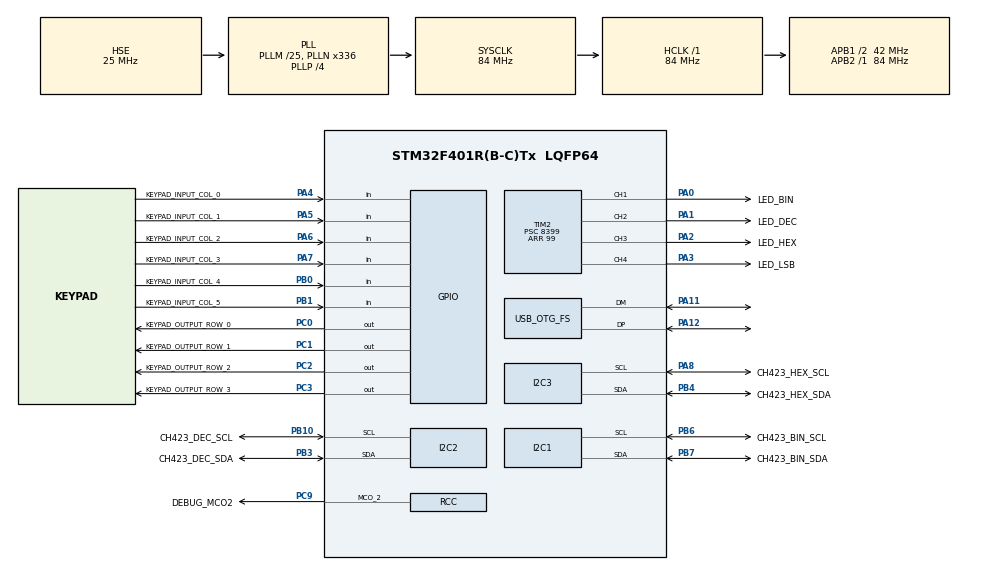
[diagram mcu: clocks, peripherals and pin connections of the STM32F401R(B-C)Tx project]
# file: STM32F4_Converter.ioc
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Dma.I2C1_TX.0.Direction=DMA_MEMORY_TO_PERIPH
Dma.I2C1_TX.0.FIFOMode=DMA_FIFOMODE_DISABLE
Dma.I2C1_TX.0.Instance=DMA1_Stream6
Dma.I2C1_TX.0.MemDataAlignment=DMA_MDATAALIGN_BYTE
Dma.I2C1_TX.0.MemInc=DMA_MINC_ENABLE
Dma.I2C1_TX.0.Mode=DMA_NORMAL
Dma.I2C1_TX.0.PeriphDataAlignment=DMA_PDATAALIGN_BYTE
Dma.I2C1_TX.0.PeriphInc=DMA_PINC_DISABLE
Dma.I2C1_TX.0.Priority=DMA_PRIORITY_LOW
Dma.I2C2_TX.1.Direction=DMA_MEMORY_TO_PERIPH
Dma.I2C2_TX.1.FIFOMode=DMA_FIFOMODE_DISABLE
Dma.I2C2_TX.1.Instance=DMA1_Stream7
Dma.I2C2_TX.1.MemDataAlignment=DMA_MDATAALIGN_BYTE
Dma.I2C2_TX.1.MemInc=DMA_MINC_ENABLE
Dma.I2C2_TX.1.Mode=DMA_NORMAL
Dma.I2C2_TX.1.PeriphDataAlignment=DMA_PDATAALIGN_BYTE
Dma.I2C2_TX.1.PeriphInc=DMA_PINC_DISABLE
Dma.I2C2_TX.1.Priority=DMA_PRIORITY_LOW
Dma.I2C3_TX.2.Direction=DMA_MEMORY_TO_PERIPH
Dma.I2C3_TX.2.FIFOMode=DMA_FIFOMODE_DISABLE
Dma.I2C3_TX.2.Instance=DMA1_Stream4
Dma.I2C3_TX.2.MemDataAlignment=DMA_MDATAALIGN_BYTE
Dma.I2C3_TX.2.MemInc=DMA_MINC_ENABLE
Dma.I2C3_TX.2.Mode=DMA_NORMAL
Dma.I2C3_TX.2.PeriphDataAlignment=DMA_PDATAALIGN_BYTE
Dma.I2C3_TX.2.PeriphInc=DMA_PINC_DISABLE
Dma.I2C3_TX.2.Priority=DMA_PRIORITY_LOW
Dma.Request0=I2C1_TX
Dma.Request1=I2C2_TX
Dma.Request2=I2C3_TX
FREERTOS.Tasks01=defaultTask,-2,512,StartDefaultTask,Default,NULL,Dynamic,NULL,NULL
I2C1.I2C_Mode=I2C_Fast
I2C2.I2C_Mode=I2C_Fast
I2C3.I2C_Mode=I2C_Fast
Mcu.Family=STM32F4
Mcu.Name=STM32F401R(B-C)Tx
Mcu.Package=LQFP64
NVIC.DMA1_Stream4_IRQn=true\:10\:0\:true\:false\:true\:true\:false\:true
NVIC.DMA1_Stream6_IRQn=true\:10\:0\:true\:false\:true\:true\:false\:true
NVIC.DMA1_Stream7_IRQn=true\:10\:0\:true\:false\:true\:true\:false\:true
NVIC.OTG_FS_IRQn=true\:15\:0\:true\:false\:true\:false\:false\:true
NVIC.PriorityGroup=NVIC_PRIORITYGROUP_4
NVIC.TIM1_UP_TIM10_IRQn=true\:0\:0\:false\:false\:true\:false\:false\:true
NVIC.TIM3_IRQn=true\:5\:0\:true\:false\:true\:true\:true\:true
NVIC.TimeBase=TIM1_UP_TIM10_IRQn
NVIC.TimeBaseIP=TIM1
PA0-WKUP.GPIO_Label=LED_BIN
PA0-WKUP.Signal=S_TIM2_CH1_ETR
PA1.GPIO_Label=LED_DEC
PA1.Signal=S_TIM2_CH2
PA11.Mode=Device_Only
PA11.Signal=USB_OTG_FS_DM
PA12.Mode=Device_Only
PA12.Signal=USB_OTG_FS_DP
PA13.GPIO_Label=SWD_SWDIO
PA13.Mode=Serial_Wire
PA13.Signal=SYS_JTMS-SWDIO
PA14.GPIO_Label=SWD_SWCLK
PA14.Mode=Serial_Wire
PA14.Signal=SYS_JTCK-SWCLK
PA2.GPIO_Label=LED_HEX
PA2.Signal=S_TIM2_CH3
PA3.GPIO_Label=LED_LSB
PA3.Signal=S_TIM2_CH4
PA4.GPIO_Label=KEYPAD_INPUT_COL_0
PA4.Signal=GPIO_Input
PA5.GPIO_Label=KEYPAD_INPUT_COL_1
PA5.Signal=GPIO_Input
PA6.GPIO_Label=KEYPAD_INPUT_COL_2
PA6.Signal=GPIO_Input
PA7.GPIO_Label=KEYPAD_INPUT_COL_3
PA7.Signal=GPIO_Input
PA8.GPIO_Label=CH423_HEX_SCL
PA8.Mode=I2C
PA8.Signal=I2C3_SCL
PB0.GPIO_Label=KEYPAD_INPUT_COL_4
PB0.Signal=GPIO_Input
PB1.GPIO_Label=KEYPAD_INPUT_COL_5
PB1.Signal=GPIO_Input
PB10.GPIO_Label=CH423_DEC_SCL
PB10.Mode=I2C
PB10.Signal=I2C2_SCL
PB3.GPIO_Label=CH423_DEC_SDA
PB3.Mode=I2C
PB3.Signal=I2C2_SDA
PB4.GPIO_Label=CH423_HEX_SDA
PB4.Mode=I2C
PB4.Signal=I2C3_SDA
PB6.GPIO_Label=CH423_BIN_SCL
PB6.Mode=I2C
PB6.Signal=I2C1_SCL
PB7.GPIO_Label=CH423_BIN_SDA
PB7.Mode=I2C
PB7.Signal=I2C1_SDA
PC0.GPIO_Label=KEYPAD_OUTPUT_ROW_0
PC0.GPIO_Speed=GPIO_SPEED_FREQ_VERY_HIGH
PC0.Signal=GPIO_Output
PC1.GPIO_Label=KEYPAD_OUTPUT_ROW_1
PC1.GPIO_Speed=GPIO_SPEED_FREQ_VERY_HIGH
PC1.Signal=GPIO_Output
PC2.GPIO_Label=KEYPAD_OUTPUT_ROW_2
PC2.GPIO_Speed=GPIO_SPEED_FREQ_VERY_HIGH
PC2.Signal=GPIO_Output
PC3.GPIO_Label=KEYPAD_OUTPUT_ROW_3
PC3.GPIO_Speed=GPIO_SPEED_FREQ_VERY_HIGH
PC3.Signal=GPIO_Output
PC9.GPIO_Label=DEBUG_MCO2
PC9.Mode=Clock-out-2
PC9.Signal=RCC_MCO_2
PH0\ -\ OSC_IN.Mode=HSE-External-Oscillator
PH0\ -\ OSC_IN.Signal=RCC_OSC_IN
PH1\ -\ OSC_OUT.Mode=HSE-External-Oscillator
PH1\ -\ OSC_OUT.Signal=RCC_OSC_OUT
ProjectManager.HeapSize=0x1000
ProjectManager.StackSize=0x1000
ProjectManager.TargetToolchain=STM32CubeIDE
RCC.48MHZClocksFreq_Value=48000000
RCC.AHBFreq_Value=84000000
RCC.APB1CLKDivider=RCC_HCLK_DIV2
RCC.APB1Freq_Value=42000000
RCC.APB1TimFreq_Value=84000000
RCC.APB2Freq_Value=84000000
RCC.APB2TimFreq_Value=84000000
RCC.CortexFreq_Value=84000000
RCC.HCLKFreq_Value=84000000
RCC.HSE_VALUE=25000000
RCC.HSI_VALUE=16000000
RCC.LSE_VALUE=32768
RCC.PLLM=25
RCC.PLLN=336
RCC.PLLP=RCC_PLLP_DIV4
RCC.PLLQ=7
RCC.RCC_MCODiv2=RCC_MCODIV_4
RCC.SYSCLKFreq_VALUE=84000000
RCC.SYSCLKSource=RCC_SYSCLKSOURCE_PLLCLK
RCC.VCOOutputFreq_Value=336000000
SH.S_TIM2_CH1_ETR.0=TIM2_CH1,PWM Generation1 CH1
SH.S_TIM2_CH2.0=TIM2_CH2,PWM Generation2 CH2
SH.S_TIM2_CH3.0=TIM2_CH3,PWM Generation3 CH3
SH.S_TIM2_CH4.0=TIM2_CH4,PWM Generation4 CH4
TIM2.AutoReloadPreload=TIM_AUTORELOAD_PRELOAD_ENABLE
TIM2.Channel-PWM\ Generation1\ CH1=TIM_CHANNEL_1
TIM2.Channel-PWM\ Generation2\ CH2=TIM_CHANNEL_2
TIM2.Channel-PWM\ Generation3\ CH3=TIM_CHANNEL_3
TIM2.Channel-PWM\ Generation4\ CH4=TIM_CHANNEL_4
TIM2.Period=99
TIM2.Prescaler=8399
TIM2.Pulse-PWM\ Generation1\ CH1=50
TIM2.Pulse-PWM\ Generation2\ CH2=50
TIM2.Pulse-PWM\ Generation3\ CH3=50
TIM2.Pulse-PWM\ Generation4\ CH4=50
TIM3.AutoReloadPreload=TIM_AUTORELOAD_PRELOAD_ENABLE
TIM3.Period=199
TIM3.Prescaler=8399
USB_DEVICE.CLASS_NAME_FS=DFU
USB_DEVICE.LANGID_STRING=1036
USB_DEVICE.MANUFACTURER_STRING=XProg
USB_DEVICE.PID_DFU_FS=0xFFFF
USB_DEVICE.PRODUCT_STRING_DFU_FS=Calculator STM32 DownLoad Firmware Update
USB_DEVICE.USBD_SELF_POWERED=0
USB_DEVICE.VID=0xFFFF
USB_DEVICE.VirtualMode=Dfu
USB_DEVICE.VirtualModeFS=Dfu_FS
USB_OTG_FS.VirtualMode=Device_Only
VP_FREERTOS_VS_CMSIS_V1.Mode=CMSIS_V1
VP_SYS_VS_tim1.Mode=TIM1
VP_TIM2_VS_ClockSourceINT.Mode=Internal
VP_TIM3_VS_ClockSourceINT.Mode=Internal
VP_USB_DEVICE_VS_USB_DEVICE_DFU_FS.Mode=DFU_FS
board=custom

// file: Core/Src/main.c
/* USER CODE BEGIN Header */
/**
  ******************************************************************************
  * @file           : main.c
  * @brief          : Main program body
  ******************************************************************************
  * @attention
  *
  * <h2><center>&copy; Copyright (c) 2020 STMicroelectronics.
  * All rights reserved.</center></h2>
  *
  * This software component is licensed by ST under Ultimate Liberty license
  * SLA0044, the "License"; You may not use this file except in compliance with
  * the License. You may obtain a copy of the License at:
  *                             www.st.com/SLA0044
  *
  ******************************************************************************
  */
/* USER CODE END Header */
#include "main.h"
#include "cmsis_os.h"
#include "usb_device.h"

/* USER CODE BEGIN Includes */
#include "display.h"
#include "keypad.h"
#include "calculator.h"
/* USER CODE END Includes */

I2C_HandleTypeDef hi2c1;
I2C_HandleTypeDef hi2c2;
I2C_HandleTypeDef hi2c3;
DMA_HandleTypeDef hdma_i2c1_tx;
DMA_HandleTypeDef hdma_i2c2_tx;
DMA_HandleTypeDef hdma_i2c3_tx;

TIM_HandleTypeDef htim2;
TIM_HandleTypeDef htim3;

osThreadId defaultTaskHandle;

void SystemClock_Config(void);
static void MX_GPIO_Init(void);
static void MX_DMA_Init(void);
static void MX_I2C1_Init(void);
static void MX_I2C2_Init(void);
static void MX_I2C3_Init(void);
static void MX_TIM2_Init(void);
static void MX_TIM3_Init(void);
void StartDefaultTask(void const * argument);

int main(void)
{

  /* MCU Configuration--------------------------------------------------------*/

  /* Reset of all peripherals, Initializes the Flash interface and the Systick. */
  HAL_Init();

  /* Configure the system clock */
  SystemClock_Config();

  /* Initialize all configured peripherals */
  MX_GPIO_Init();
  MX_DMA_Init();
  MX_I2C1_Init();
  MX_I2C2_Init();
  MX_I2C3_Init();
  MX_TIM2_Init();
  MX_TIM3_Init();

  /* Create the thread(s) */
  /* definition and creation of defaultTask */
  osThreadDef(defaultTask, StartDefaultTask, osPriorityLow, 0, 512);
  defaultTaskHandle = osThreadCreate(osThread(defaultTask), NULL);

  /* USER CODE BEGIN RTOS_THREADS */
  keypad_Task_create();
  display_Task_create();
  calculator_Task_create();
  /* USER CODE END RTOS_THREADS */

  /* Start scheduler */
  osKernelStart();

  /* We should never get here as control is now taken by the scheduler */
  /* Infinite loop */
  while (1)
  {

  }
}

void SystemClock_Config(void)
{
  RCC_OscInitTypeDef RCC_OscInitStruct = {0};
  RCC_ClkInitTypeDef RCC_ClkInitStruct = {0};

  /** Configure the main internal regulator output voltage
  */
  __HAL_RCC_PWR_CLK_ENABLE();
  __HAL_PWR_VOLTAGESCALING_CONFIG(PWR_REGULATOR_VOLTAGE_SCALE2);
  /** Initializes the RCC Oscillators according to the specified parameters
  * in the RCC_OscInitTypeDef structure.
  */
  RCC_OscInitStruct.OscillatorType = RCC_OSCILLATORTYPE_HSE;
  RCC_OscInitStruct.HSEState = RCC_HSE_ON;
  RCC_OscInitStruct.PLL.PLLState = RCC_PLL_ON;
  RCC_OscInitStruct.PLL.PLLSource = RCC_PLLSOURCE_HSE;
  RCC_OscInitStruct.PLL.PLLM = 25;
  RCC_OscInitStruct.PLL.PLLN = 336;
  RCC_OscInitStruct.PLL.PLLP = RCC_PLLP_DIV4;
  RCC_OscInitStruct.PLL.PLLQ = 7;
  if (HAL_RCC_OscConfig(&RCC_OscInitStruct) != HAL_OK)
  {
    Error_Handler();
  }
  /** Initializes the CPU, AHB and APB buses clocks
  */
  RCC_ClkInitStruct.ClockType = RCC_CLOCKTYPE_HCLK|RCC_CLOCKTYPE_SYSCLK
                              |RCC_CLOCKTYPE_PCLK1|RCC_CLOCKTYPE_PCLK2;
  RCC_ClkInitStruct.SYSCLKSource = RCC_SYSCLKSOURCE_PLLCLK;
  RCC_ClkInitStruct.AHBCLKDivider = RCC_SYSCLK_DIV1;
  RCC_ClkInitStruct.APB1CLKDivider = RCC_HCLK_DIV2;
  RCC_ClkInitStruct.APB2CLKDivider = RCC_HCLK_DIV1;

  if (HAL_RCC_ClockConfig(&RCC_ClkInitStruct, FLASH_LATENCY_2) != HAL_OK)
  {
    Error_Handler();
  }
  HAL_RCC_MCOConfig(RCC_MCO2, RCC_MCO2SOURCE_SYSCLK, RCC_MCODIV_4);
}

static void MX_I2C1_Init(void)
{

  hi2c1.Instance = I2C1;
  hi2c1.Init.ClockSpeed = 400000;
  hi2c1.Init.DutyCycle = I2C_DUTYCYCLE_2;
  hi2c1.Init.OwnAddress1 = 0;
  hi2c1.Init.AddressingMode = I2C_ADDRESSINGMODE_7BIT;
  hi2c1.Init.DualAddressMode = I2C_DUALADDRESS_DISABLE;
  hi2c1.Init.OwnAddress2 = 0;
  hi2c1.Init.GeneralCallMode = I2C_GENERALCALL_DISABLE;
  hi2c1.Init.NoStretchMode = I2C_NOSTRETCH_DISABLE;
  if (HAL_I2C_Init(&hi2c1) != HAL_OK)
  {
    Error_Handler();
  }

}

static void MX_I2C2_Init(void)
{

  hi2c2.Instance = I2C2;
  hi2c2.Init.ClockSpeed = 400000;
  hi2c2.Init.DutyCycle = I2C_DUTYCYCLE_2;
  hi2c2.Init.OwnAddress1 = 0;
  hi2c2.Init.AddressingMode = I2C_ADDRESSINGMODE_7BIT;
  hi2c2.Init.DualAddressMode = I2C_DUALADDRESS_DISABLE;
  hi2c2.Init.OwnAddress2 = 0;
  hi2c2.Init.GeneralCallMode = I2C_GENERALCALL_DISABLE;
  hi2c2.Init.NoStretchMode = I2C_NOSTRETCH_DISABLE;
  if (HAL_I2C_Init(&hi2c2) != HAL_OK)
  {
    Error_Handler();
  }

}

static void MX_I2C3_Init(void)
{

  hi2c3.Instance = I2C3;
  hi2c3.Init.ClockSpeed = 400000;
  hi2c3.Init.DutyCycle = I2C_DUTYCYCLE_2;
  hi2c3.Init.OwnAddress1 = 0;
  hi2c3.Init.AddressingMode = I2C_ADDRESSINGMODE_7BIT;
  hi2c3.Init.DualAddressMode = I2C_DUALADDRESS_DISABLE;
  hi2c3.Init.OwnAddress2 = 0;
  hi2c3.Init.GeneralCallMode = I2C_GENERALCALL_DISABLE;
  hi2c3.Init.NoStretchMode = I2C_NOSTRETCH_DISABLE;
  if (HAL_I2C_Init(&hi2c3) != HAL_OK)
  {
    Error_Handler();
  }

}

static void MX_TIM2_Init(void)
{

  TIM_ClockConfigTypeDef sClockSourceConfig = {0};
  TIM_MasterConfigTypeDef sMasterConfig = {0};
  TIM_OC_InitTypeDef sConfigOC = {0};

  htim2.Instance = TIM2;
  htim2.Init.Prescaler = 8399;
  htim2.Init.CounterMode = TIM_COUNTERMODE_UP;
  htim2.Init.Period = 99;
  htim2.Init.ClockDivision = TIM_CLOCKDIVISION_DIV1;
  htim2.Init.AutoReloadPreload = TIM_AUTORELOAD_PRELOAD_ENABLE;
  if (HAL_TIM_Base_Init(&htim2) != HAL_OK)
  {
    Error_Handler();
  }
  sClockSourceConfig.ClockSource = TIM_CLOCKSOURCE_INTERNAL;
  if (HAL_TIM_ConfigClockSource(&htim2, &sClockSourceConfig) != HAL_OK)
  {
    Error_Handler();
  }
  if (HAL_TIM_PWM_Init(&htim2) != HAL_OK)
  {
    Error_Handler();
  }
  sMasterConfig.MasterOutputTrigger = TIM_TRGO_RESET;
  sMasterConfig.MasterSlaveMode = TIM_MASTERSLAVEMODE_DISABLE;
  if (HAL_TIMEx_MasterConfigSynchronization(&htim2, &sMasterConfig) != HAL_OK)
  {
    Error_Handler();
  }
  sConfigOC.OCMode = TIM_OCMODE_PWM1;
  sConfigOC.Pulse = 50;
  sConfigOC.OCPolarity = TIM_OCPOLARITY_HIGH;
  sConfigOC.OCFastMode = TIM_OCFAST_DISABLE;
  if (HAL_TIM_PWM_ConfigChannel(&htim2, &sConfigOC, TIM_CHANNEL_1) != HAL_OK)
  {
    Error_Handler();
  }
  if (HAL_TIM_PWM_ConfigChannel(&htim2, &sConfigOC, TIM_CHANNEL_2) != HAL_OK)
  {
    Error_Handler();
  }
  if (HAL_TIM_PWM_ConfigChannel(&htim2, &sConfigOC, TIM_CHANNEL_3) != HAL_OK)
  {
    Error_Handler();
  }
  if (HAL_TIM_PWM_ConfigChannel(&htim2, &sConfigOC, TIM_CHANNEL_4) != HAL_OK)
  {
    Error_Handler();
  }
  HAL_TIM_MspPostInit(&htim2);

}

static void MX_TIM3_Init(void)
{

  TIM_ClockConfigTypeDef sClockSourceConfig = {0};
  TIM_MasterConfigTypeDef sMasterConfig = {0};

  htim3.Instance = TIM3;
  htim3.Init.Prescaler = 8399;
  htim3.Init.CounterMode = TIM_COUNTERMODE_UP;
  htim3.Init.Period = 199;
  htim3.Init.ClockDivision = TIM_CLOCKDIVISION_DIV1;
  htim3.Init.AutoReloadPreload = TIM_AUTORELOAD_PRELOAD_ENABLE;
  if (HAL_TIM_Base_Init(&htim3) != HAL_OK)
  {
    Error_Handler();
  }
  sClockSourceConfig.ClockSource = TIM_CLOCKSOURCE_INTERNAL;
  if (HAL_TIM_ConfigClockSource(&htim3, &sClockSourceConfig) != HAL_OK)
  {
    Error_Handler();
  }
  sMasterConfig.MasterOutputTrigger = TIM_TRGO_RESET;
  sMasterConfig.MasterSlaveMode = TIM_MASTERSLAVEMODE_DISABLE;
  if (HAL_TIMEx_MasterConfigSynchronization(&htim3, &sMasterConfig) != HAL_OK)
  {
    Error_Handler();
  }

}

static void MX_DMA_Init(void)
{

  /* DMA controller clock enable */
  __HAL_RCC_DMA1_CLK_ENABLE();

  /* DMA interrupt init */
  /* DMA1_Stream4_IRQn interrupt configuration */
  HAL_NVIC_SetPriority(DMA1_Stream4_IRQn, 10, 0);
  HAL_NVIC_EnableIRQ(DMA1_Stream4_IRQn);
  /* DMA1_Stream6_IRQn interrupt configuration */
  HAL_NVIC_SetPriority(DMA1_Stream6_IRQn, 10, 0);
  HAL_NVIC_EnableIRQ(DMA1_Stream6_IRQn);
  /* DMA1_Stream7_IRQn interrupt configuration */
  HAL_NVIC_SetPriority(DMA1_Stream7_IRQn, 10, 0);
  HAL_NVIC_EnableIRQ(DMA1_Stream7_IRQn);

}

static void MX_GPIO_Init(void)
{
  GPIO_InitTypeDef GPIO_InitStruct = {0};

  /* GPIO Ports Clock Enable */
  __HAL_RCC_GPIOH_CLK_ENABLE();
  __HAL_RCC_GPIOC_CLK_ENABLE();
  __HAL_RCC_GPIOA_CLK_ENABLE();
  __HAL_RCC_GPIOB_CLK_ENABLE();

  /*Configure GPIO pin Output Level */
  HAL_GPIO_WritePin(GPIOC, KEYPAD_OUTPUT_ROW_0_Pin|KEYPAD_OUTPUT_ROW_1_Pin|KEYPAD_OUTPUT_ROW_2_Pin|KEYPAD_OUTPUT_ROW_3_Pin, GPIO_PIN_RESET);

  /*Configure GPIO pins : KEYPAD_OUTPUT_ROW_0_Pin KEYPAD_OUTPUT_ROW_1_Pin KEYPAD_OUTPUT_ROW_2_Pin KEYPAD_OUTPUT_ROW_3_Pin */
  GPIO_InitStruct.Pin = KEYPAD_OUTPUT_ROW_0_Pin|KEYPAD_OUTPUT_ROW_1_Pin|KEYPAD_OUTPUT_ROW_2_Pin|KEYPAD_OUTPUT_ROW_3_Pin;
  GPIO_InitStruct.Mode = GPIO_MODE_OUTPUT_PP;
  GPIO_InitStruct.Pull = GPIO_NOPULL;
  GPIO_InitStruct.Speed = GPIO_SPEED_FREQ_VERY_HIGH;
  HAL_GPIO_Init(GPIOC, &GPIO_InitStruct);

  /*Configure GPIO pins : KEYPAD_INPUT_COL_0_Pin KEYPAD_INPUT_COL_1_Pin KEYPAD_INPUT_COL_2_Pin KEYPAD_INPUT_COL_3_Pin */
  GPIO_InitStruct.Pin = KEYPAD_INPUT_COL_0_Pin|KEYPAD_INPUT_COL_1_Pin|KEYPAD_INPUT_COL_2_Pin|KEYPAD_INPUT_COL_3_Pin;
  GPIO_InitStruct.Mode = GPIO_MODE_INPUT;
  GPIO_InitStruct.Pull = GPIO_NOPULL;
  HAL_GPIO_Init(GPIOA, &GPIO_InitStruct);

  /*Configure GPIO pins : KEYPAD_INPUT_COL_4_Pin KEYPAD_INPUT_COL_5_Pin */
  GPIO_InitStruct.Pin = KEYPAD_INPUT_COL_4_Pin|KEYPAD_INPUT_COL_5_Pin;
  GPIO_InitStruct.Mode = GPIO_MODE_INPUT;
  GPIO_InitStruct.Pull = GPIO_NOPULL;
  HAL_GPIO_Init(GPIOB, &GPIO_InitStruct);

  /*Configure GPIO pin : DEBUG_MCO2_Pin */
  GPIO_InitStruct.Pin = DEBUG_MCO2_Pin;
  GPIO_InitStruct.Mode = GPIO_MODE_AF_PP;
  GPIO_InitStruct.Pull = GPIO_NOPULL;
  GPIO_InitStruct.Speed = GPIO_SPEED_FREQ_LOW;
  GPIO_InitStruct.Alternate = GPIO_AF0_MCO;
  HAL_GPIO_Init(DEBUG_MCO2_GPIO_Port, &GPIO_InitStruct);

}

void StartDefaultTask(void const * argument)
{
  /* init code for USB_DEVICE */
  MX_USB_DEVICE_Init();
  /* USER CODE BEGIN 5 */

  /* Infinite loop */
  for(;;)
  {
    osDelay(1000);
  }
  /* USER CODE END 5 */
}

void HAL_TIM_PeriodElapsedCallback(TIM_HandleTypeDef *htim)
{
  if (htim->Instance == TIM1) {
    HAL_IncTick();
  }
  /* USER CODE BEGIN Callback 1 */
  else if (htim->Instance == TIM2)
  {
      // PWM LED
  }
  else if (htim->Instance == TIM3)
  {
      // Keyboard
      keypad_sendMsg(E_KEYPAD_MSG_ID_REFRESH);
  }
  /* USER CODE END Callback 1 */
}

void Error_Handler(void)
{
}

/************************ (C) COPYRIGHT STMicroelectronics *****END OF FILE****/
